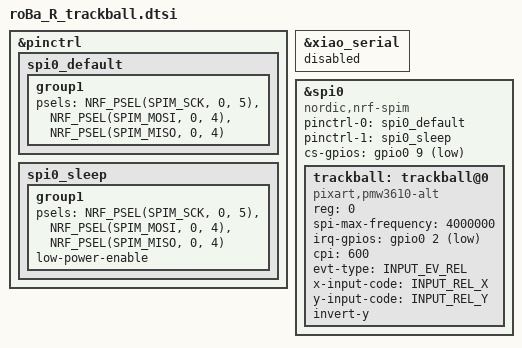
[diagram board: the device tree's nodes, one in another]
&pinctrl {
    spi0_default: spi0_default {
        group1 {
            psels = <NRF_PSEL(SPIM_SCK, 0, 5)>,
                <NRF_PSEL(SPIM_MOSI, 0, 4)>,
                <NRF_PSEL(SPIM_MISO, 0, 4)>;
        };
    };

    spi0_sleep: spi0_sleep {
        group1 {
            psels = <NRF_PSEL(SPIM_SCK, 0, 5)>,
                <NRF_PSEL(SPIM_MOSI, 0, 4)>,
                <NRF_PSEL(SPIM_MISO, 0, 4)>;
            low-power-enable;
        };
    };
};

&xiao_serial { status = "disabled"; };

&spi0 {
    compatible = "nordic,nrf-spim";
    status = "disabled";

    trackball: trackball@0 {
        compatible = "pixart,pmw3610-alt";
        status = "disabled";
        reg = <0>;
        spi-max-frequency = <4000000>;
    };
};

&spi0 {
    status = "okay";
    pinctrl-0 = <&spi0_default>;
    pinctrl-1 = <&spi0_sleep>;
    pinctrl-names = "default", "sleep";
    cs-gpios = <&gpio0 9 GPIO_ACTIVE_LOW>;
};

#include <zephyr/dt-bindings/input/input-event-codes.h>

&trackball {
    status = "okay";
    irq-gpios = <&gpio0 2 (GPIO_ACTIVE_LOW | GPIO_PULL_UP)>;
    cpi = <600>;
    evt-type = <INPUT_EV_REL>;
    x-input-code = <INPUT_REL_X>;
    y-input-code = <INPUT_REL_Y>;
    invert-y;
};
